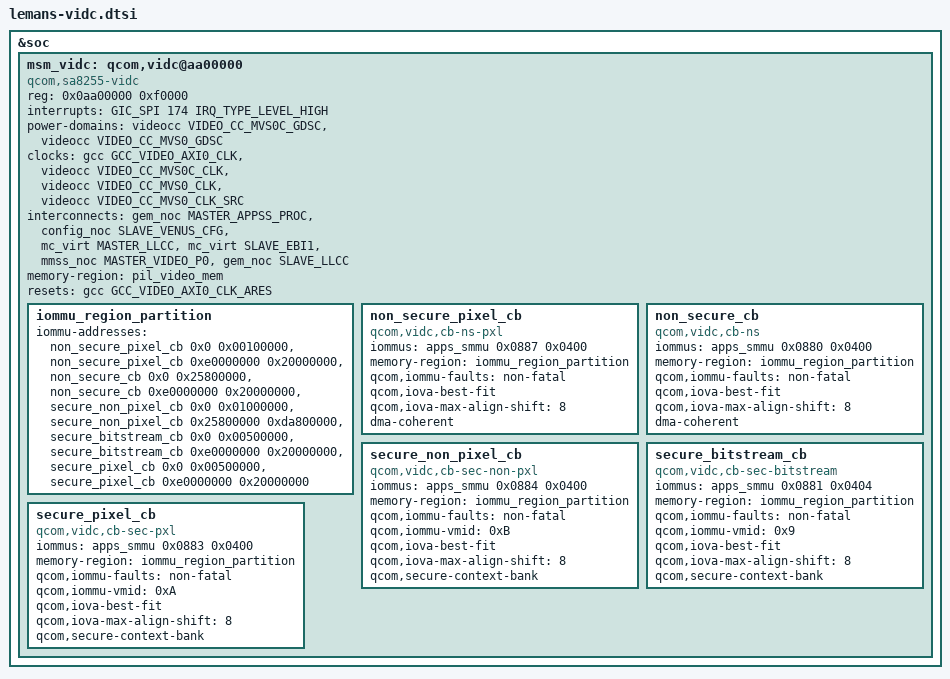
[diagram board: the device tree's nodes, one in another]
&soc {
	msm_vidc: qcom,vidc@aa00000 {
		compatible = "qcom,sa8255-vidc";
		status = "okay";

		/* IOMMU Config */
		#address-cells = <1>;
		#size-cells = <1>;

		reg = <0x0aa00000 0xf0000>;
		interrupts = <GIC_SPI 174 IRQ_TYPE_LEVEL_HIGH>;

		/* Power Domains */
		power-domains = <&videocc VIDEO_CC_MVS0C_GDSC>,
                		<&videocc VIDEO_CC_MVS0_GDSC>;
		power-domain-names = "iris-ctl", "vcodec";

		/* Clocks */
		clocks = <&gcc GCC_VIDEO_AXI0_CLK>,
			 <&videocc VIDEO_CC_MVS0C_CLK>,
			 <&videocc VIDEO_CC_MVS0_CLK>,
			 <&videocc VIDEO_CC_MVS0_CLK_SRC>;
		clock-names =
			 "gcc_video_axi0",
			 "core_clk",
			 "vcodec_clk",
			 "video_cc_mvs0_clk_src";

		/* Bus Interconnects */
		interconnects =
			 <&gem_noc MASTER_APPSS_PROC &config_noc SLAVE_VENUS_CFG>,
			 <&mc_virt MASTER_LLCC &mc_virt SLAVE_EBI1>,
			 <&mmss_noc MASTER_VIDEO_P0 &gem_noc SLAVE_LLCC>;
		interconnect-names =
			 "venus-cnoc",
			 "venus-ddr",
			 "venus-llcc";

		/* FW load region */
		memory-region = <&pil_video_mem>;

		/* Clock Resets */
		resets = <&gcc GCC_VIDEO_AXI0_CLK_ARES>;
		reset-names = "video_axi_reset";

		/* MMUs */
		iommu_region_partition: iommu_region_partition {
			/* These IOVA regions are unique per context bank */
			iommu-addresses =
				<&non_secure_pixel_cb 0x0 0x00100000>,
				<&non_secure_pixel_cb 0xe0000000 0x20000000>,
				<&non_secure_cb 0x0 0x25800000>,
				<&non_secure_cb 0xe0000000 0x20000000>,
				<&secure_non_pixel_cb 0x0 0x01000000>,
				<&secure_non_pixel_cb 0x25800000 0xda800000>,
				<&secure_bitstream_cb 0x0 0x00500000>,
				<&secure_bitstream_cb 0xe0000000 0x20000000>,
				<&secure_pixel_cb 0x0 0x00500000>,
				<&secure_pixel_cb 0xe0000000 0x20000000>;
		};

		non_secure_pixel_cb {
			compatible = "qcom,vidc,cb-ns-pxl";
			iommus = <&apps_smmu 0x0887 0x0400>;
			memory-region = <&iommu_region_partition>;
			qcom,iommu-faults = "non-fatal";
			qcom,iova-best-fit;
			qcom,iova-max-align-shift = <8>; /* 1 MB */
			dma-coherent;
		};

		non_secure_cb {
			compatible = "qcom,vidc,cb-ns";
			iommus = <&apps_smmu 0x0880 0x0400>;
			memory-region = <&iommu_region_partition>;
			qcom,iommu-faults = "non-fatal";
			qcom,iova-best-fit;
			qcom,iova-max-align-shift = <8>; /* 1 MB */
			dma-coherent;
		};

		secure_non_pixel_cb {
			compatible = "qcom,vidc,cb-sec-non-pxl";
			iommus = <&apps_smmu 0x0884 0x0400>;
			memory-region = <&iommu_region_partition>;
			qcom,iommu-faults = "non-fatal";
			qcom,iommu-vmid = <0xB>; /* VMID_CP_NON_PIXEL */
			qcom,iova-best-fit;
			qcom,iova-max-align-shift = <8>; /* 1 MB */
			qcom,secure-context-bank;
		};

		secure_bitstream_cb {
			compatible = "qcom,vidc,cb-sec-bitstream";
			iommus = <&apps_smmu 0x0881 0x0404>;
			memory-region = <&iommu_region_partition>;
			qcom,iommu-faults = "non-fatal";
			qcom,iommu-vmid = <0x9>; /* VMID_CP_BITSTREAM */
			qcom,iova-best-fit;
			qcom,iova-max-align-shift = <8>; /* 1 MB */
			qcom,secure-context-bank;
		};

		secure_pixel_cb {
			compatible = "qcom,vidc,cb-sec-pxl";
			iommus = <&apps_smmu 0x0883 0x0400>;
			memory-region = <&iommu_region_partition>;
			qcom,iommu-faults = "non-fatal";
			qcom,iommu-vmid = <0xA>; /* VMID_CP_PIXEL */
			qcom,iova-best-fit;
			qcom,iova-max-align-shift = <8>; /* 1 MB */
			qcom,secure-context-bank;
		};
	};
};
